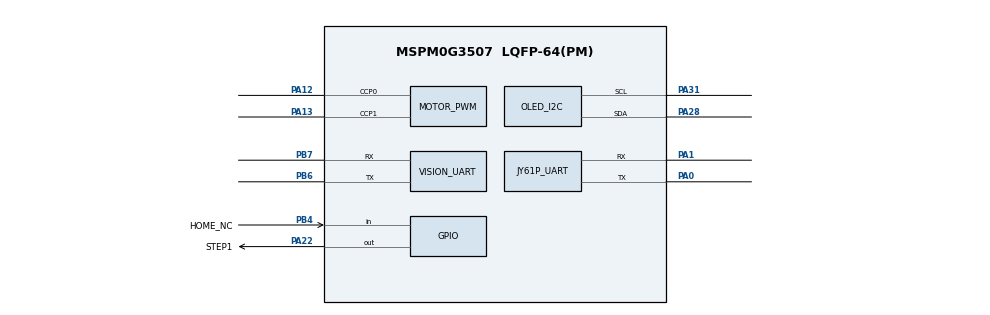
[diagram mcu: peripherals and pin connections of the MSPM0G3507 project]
/** @file system.syscfg
 *  @brief H-task chassis, sensors, UI, MaixCAM, JY61P and beam actuator.
 *  This is the only editable source for generated ti_msp_dl_config files.
 */
//@cliArgs --device "MSPM0G350X" --package "LQFP-64(PM)" --part "Default"
//@v2CliArgs --device "MSPM0G3507" --package "LQFP-64(PM)" --product "mspm0_sdk@2.10.00.04"
//@versions {"tool":"1.26.2+4477"}
// @cliArgs --board /ti/boards/LP_MSPM0G3507 --rtos nortos

const SYSCTL = scripting.addModule("/ti/driverlib/SYSCTL");
const Board  = scripting.addModule("/ti/driverlib/Board", {}, false);
const GPIO   = scripting.addModule("/ti/driverlib/GPIO", {}, false);
const PWM    = scripting.addModule("/ti/driverlib/PWM", {}, false);
const I2C    = scripting.addModule("/ti/driverlib/I2C", {}, false);
const UART   = scripting.addModule("/ti/driverlib/UART", {}, false);
const TIMER  = scripting.addModule("/ti/driverlib/TIMER", {}, false);
SYSCTL.forceDefaultClkConfig = true;
SYSCTL.clockTreeEn = true;

const MOTOR_PWM = PWM.addInstance();
MOTOR_PWM.$name = "MOTOR_PWM";
MOTOR_PWM.clockPrescale = 1;
MOTOR_PWM.timerCount = 1600;
MOTOR_PWM.peripheral.$assign = "TIMG0";
MOTOR_PWM.peripheral.ccp0Pin.$assign = "PA12";
MOTOR_PWM.peripheral.ccp1Pin.$assign = "PA13";
MOTOR_PWM.PWM_CHANNEL_0.$name = "RIGHT_PWM";
MOTOR_PWM.PWM_CHANNEL_0.dutyCycle = 0;
MOTOR_PWM.PWM_CHANNEL_0.ccValue = 1600;
MOTOR_PWM.PWM_CHANNEL_1.$name = "LEFT_PWM";
MOTOR_PWM.PWM_CHANNEL_1.dutyCycle = 0;
MOTOR_PWM.PWM_CHANNEL_1.ccValue = 1600;

/* Outputs power up low so the chassis cannot move during reset. */
const MOTOR_GPIO = GPIO.addInstance();
MOTOR_GPIO.$name = "MOTOR_DIR";
MOTOR_GPIO.associatedPins.create(5);
const motorNames = ["RIGHT_IN1", "RIGHT_IN2", "LEFT_IN1", "LEFT_IN2", "STBY"];
const motorPins = ["PB17", "PB19", "PA16", "PB24", "PB5"];
for (let index = 0; index < 5; index++) {
    MOTOR_GPIO.associatedPins[index].$name = motorNames[index];
    MOTOR_GPIO.associatedPins[index].initialValue = "CLEARED";
    MOTOR_GPIO.associatedPins[index].pin.$assign = motorPins[index];
}

/* D1 is the physical left-most sensor. */
const LINE_SENSOR_GPIO = GPIO.addInstance();
LINE_SENSOR_GPIO.$name = "LINE_SENSOR";
LINE_SENSOR_GPIO.associatedPins.create(8);
const linePins = ["PB25", "PB18", "PB21", "PB22", "PA30", "PB0", "PB1", "PB10"];
for (let index = 0; index < 8; index++) {
    LINE_SENSOR_GPIO.associatedPins[index].$name = "D" + (index + 1);
    LINE_SENSOR_GPIO.associatedPins[index].direction = "INPUT";
    LINE_SENSOR_GPIO.associatedPins[index].internalResistor = "PULL_DOWN";
    LINE_SENSOR_GPIO.associatedPins[index].pin.$assign = linePins[index];
}

const ENCODER_GPIO = GPIO.addInstance();
ENCODER_GPIO.$name = "ENCODER";
ENCODER_GPIO.associatedPins.create(4);
const encoderNames = ["LEFT_A", "LEFT_B", "RIGHT_A", "RIGHT_B"];
const encoderPins = ["PA25", "PA14", "PA26", "PA27"];
for (let index = 0; index < 4; index++) {
    ENCODER_GPIO.associatedPins[index].$name = encoderNames[index];
    ENCODER_GPIO.associatedPins[index].direction = "INPUT";
    ENCODER_GPIO.associatedPins[index].interruptEn = true;
    ENCODER_GPIO.associatedPins[index].polarity = "RISE_FALL";
    ENCODER_GPIO.associatedPins[index].pin.$assign = encoderPins[index];
}

const OLED_I2C = I2C.addInstance();
OLED_I2C.$name = "OLED_I2C";
OLED_I2C.basicEnableController = true;
OLED_I2C.basicControllerBusSpeed = 400000;
OLED_I2C.advAnalogGlitchFilter = "DISABLED";
OLED_I2C.peripheral.$assign = "I2C0";
OLED_I2C.peripheral.sdaPin.$assign = "PA28";
OLED_I2C.peripheral.sclPin.$assign = "PA31";

/* MaixCAM Pro BALL_ROD_POSITION V3, 115200-8-N-1, 3.3 V TTL. */
const VISION_UART = UART.addInstance();
VISION_UART.$name = "VISION_UART";
VISION_UART.profile = "CUSTOM";
VISION_UART.enableInternalLoopback = false;
VISION_UART.peripheral.$assign = "UART1";
VISION_UART.targetBaudRate = 115200;
VISION_UART.enabledInterrupts = ["RX"];
VISION_UART.enableFIFO = false;
VISION_UART.peripheral.txPin.$assign = "PB6";
VISION_UART.peripheral.rxPin.$assign = "PB7";

/*
 * Vehicle-mounted JY61P.  9600 baud is the factory default used by the
 * current module family; change only this targetBaudRate if the sensor was
 * reconfigured with its host tool.
 */
const JY61P_UART = UART.addInstance();
JY61P_UART.$name = "JY61P_UART";
JY61P_UART.profile = "CUSTOM";
JY61P_UART.enableInternalLoopback = false;
JY61P_UART.peripheral.$assign = "UART0";
JY61P_UART.targetBaudRate = 9600;
JY61P_UART.enabledInterrupts = ["RX"];
JY61P_UART.enableFIFO = false;
JY61P_UART.peripheral.txPin.$assign = "PA0";
JY61P_UART.peripheral.rxPin.$assign = "PA1";

/*
 * 20 kHz scheduler for STEP rising edges.  PA22 remains a GPIO because the
 * software planner changes rate and direction while retaining an exact
 * signed step count.
 */
const STEP_TIMER = TIMER.addInstance();
STEP_TIMER.$name = "STEP_TIMER";
STEP_TIMER.timerMode = "PERIODIC";
STEP_TIMER.timerPeriod = "50 us";
STEP_TIMER.interrupts = ["ZERO"];
STEP_TIMER.timerStartTimer = true;
STEP_TIMER.peripheral.$assign = "TIMG6";

/*
 * D36A axis 1: STEP=PA22, DIR=PA17 and active-high EN=PB12.
 * HOME_NC is a normally-closed lower switch wired PB4--GND.  It reads high
 * when the switch opens at the lower stop or when its wire breaks.
 */
const BEAM_GPIO = GPIO.addInstance();
BEAM_GPIO.$name = "BEAM_IO";
BEAM_GPIO.associatedPins.create(2);
BEAM_GPIO.associatedPins[0].$name = "STEP1";
BEAM_GPIO.associatedPins[0].initialValue = "CLEARED";
BEAM_GPIO.associatedPins[0].pin.$assign = "PA22";
BEAM_GPIO.associatedPins[1].$name = "HOME_NC";
BEAM_GPIO.associatedPins[1].direction = "INPUT";
BEAM_GPIO.associatedPins[1].internalResistor = "PULL_UP";
BEAM_GPIO.associatedPins[1].pin.$assign = "PB4";

/*
 * KEY1..KEY4 are active-low.  BUZZER on PA7 is active-high.  The legacy
 * STEPPERx_EN_N generated names are retained to avoid a broad macro rename,
 * but D36A EN is active-high.  Both axes power up disabled (low).
 */
const SYSTEM_GPIO = GPIO.addInstance();
SYSTEM_GPIO.$name = "SYSTEM_IO";
SYSTEM_GPIO.associatedPins.create(9);
const systemNames = [
    "STEPPER1_DIR", "STEPPER1_EN_N", "STEPPER2_DIR", "STEPPER2_EN_N",
    "KEY1_N", "KEY2_N", "KEY3_N", "KEY4_N", "BUZZER"
];
const systemPins = [
    "PA17", "PB12", "PB16", "PB13",
    "PB2", "PB3", "PB23", "PB15", "PA7"
];
for (let index = 0; index < 9; index++) {
    SYSTEM_GPIO.associatedPins[index].$name = systemNames[index];
    SYSTEM_GPIO.associatedPins[index].pin.$assign = systemPins[index];
}
SYSTEM_GPIO.associatedPins[0].initialValue = "CLEARED";
SYSTEM_GPIO.associatedPins[1].initialValue = "CLEARED";
SYSTEM_GPIO.associatedPins[2].initialValue = "CLEARED";
SYSTEM_GPIO.associatedPins[3].initialValue = "CLEARED";
for (let index = 4; index < 8; index++) {
    SYSTEM_GPIO.associatedPins[index].direction = "INPUT";
    SYSTEM_GPIO.associatedPins[index].internalResistor = "PULL_UP";
}
SYSTEM_GPIO.associatedPins[8].initialValue = "CLEARED";
